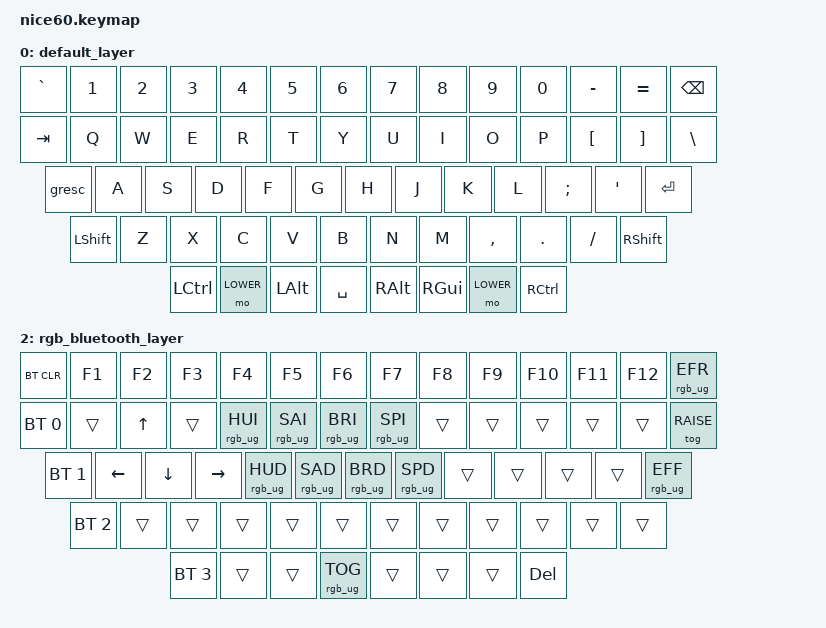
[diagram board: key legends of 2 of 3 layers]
/*
 * Copyright (c) 2021 Nick Winans
 *
 * SPDX-License-Identifier: MIT
 */

#include <behaviors.dtsi>
#include <dt-bindings/zmk/keys.h>
#include <dt-bindings/zmk/rgb.h>
#include <dt-bindings/zmk/bt.h>
#include <dt-bindings/zmk/outputs.h>
#include <dt-bindings/zmk/reset.h>
#include <dt-bindings/zmk/ext_power.h>

#define DEFAULT 0
#define LOWER   1
#define RAISE   2
/ {

behaviors {
        hm: homerow_mods {
            compatible = "zmk,behavior-hold-tap";
            label = "SPACE_FN_MODS";
            #binding-cells = <2>;
            tapping-term-ms = <400>;
            quick_tap_ms = <0>;
            flavor = "tap-preferred";
            bindings = <&mo>, <&kp>;
        };
    };
   
	keymap {
		compatible = "zmk,keymap";
		
		default_layer {
// ------------------------------------------------------------------------------------------
// | ` |  1  |  2  |  3  |  4  |  5  |  6  |  7  |  8  |  9  |  0  |  -  |  =  |   BKSP   |
// | TAB  |  Q  |  W  |  E  |  R  |  T  |  Y  |  U  |  I  |  O  |  P  |  [  |  ]  |   \     |
// | ESC  |  A  |  S  |  D  |  F  |  G  |  H  |  J  |  K  |  L  |  ;  |  '  |     ENTER    |
// |  SHIFT  |  Z  |  X  |  C  |  V  |  B  |  N  |  M  |  ,  |  .  |  /  |      SHIFT       |
// |  CTL  |  LOWER  |  ALT  |            SPACE              |  ALT  |  LOWER  |  WIN |  CTL  |
// ------------------------------------------------------------------------------------------
			bindings = <
	&kp GRAVE &kp N1 &kp N2 &kp N3 &kp N4 &kp N5 &kp N6 &kp N7 &kp N8 &kp N9 &kp N0 &kp MINUS &kp EQUAL  &kp BSPC
	&kp TAB  &kp Q  &kp W  &kp E  &kp R  &kp T  &kp Y  &kp U  &kp I  &kp O  &kp P  &kp LBKT  &kp RBKT  &kp BSLH
	&gresc  &kp A  &kp S  &kp D  &kp F  &kp G  &kp H  &kp J  &kp K  &kp L  &kp SEMI &kp SQT           &kp RET
	&kp LSHFT   &kp Z  &kp X  &kp C  &kp V  &kp B  &kp N  &kp M  &kp COMMA &kp DOT &kp FSLH           &kp RSHFT
	&kp LCTRL &mo LOWER &kp LALT             &kp SPACE                    &kp RALT &kp RGUI  &mo LOWER   &kp RCTRL
			>;
		};
		
		function_media_layer {
// --------------------------------------------------------------------------------------------------
// |       |  F1  |  F2  |  F3  |  F4  |  F5  |  F6  |  F7  |  F8  |  F9  |  F10      |  F11     |  F12     | BKSP |
// |       | BRIDN|BRIUP |      |      |      |      |      |      |      |   PAUSE   |  VOL UP  |  VOL DN  | RAISE |
// |       |      |      |      |      |      |  LT  | DOWN |  UP  |  RT  |           |          |                 |
// |       |      |      |      |      |      |      |      |      |      |           |          |                 |
// |       |      |      |                  SLEEP                         |           |          |          |      |
// --------------------------------------------------------------------------------------------------
			bindings = <
	&trans    &kp F1   &kp F2    &kp F3   &kp F4    &kp F5     &kp F6  &kp F7   &kp F8   &kp F9     &kp F10   &kp F11       &kp F12        &kp BSPC
	&trans    &kp C_BRI_DN   &kp C_BRI_UP    &trans   &trans    &trans     &trans  &trans   &trans   &trans     &kp C_PP  &kp C_VOL_DN  &kp C_VOL_UP   &tog RAISE 
	&trans  &trans  &trans  &trans  &trans  &trans  &kp LEFT  &kp DOWN  &kp UP  &kp RIGHT  &trans &trans           &trans                     
	&trans &trans   &trans    &trans   &trans    &trans  &trans &trans  &trans   &trans  &trans       &trans                     &trans
	&trans    &trans   &trans                            &kp C_SLEEP                                     &trans    &trans        &trans         &trans
			>;
		};

		rgb_bluetooth_layer {
// ------------------------------------------------------------------------------------------------
// | BT CLR | F1  | F2  | F3  | F4  | F5  | F6  | F7  | F8  | F9  | F10  | F11 | F12 | EFFECT REV |
// |  BT 1   |   |  UP |   | HUEUP | SATUP | BRIUP | SPDUP |   |     |    |     |     |  RAISE    |
// |   BT 2   | LT |  DN  | RT | HUEDN | SATDN | BRIDN | SPDDN |   |     |   |     |  EFFECT FORW |
// |    BT 3     |     |      |      |     |     |     |     |     |     |     |                  |
// |   BT 4  |      |      |             TOG RGB                |     |       |       |  DEL  |
// ------------------------------------------------------------------------------------------------
			bindings = <
	&bt BT_CLR   &kp F1    &kp F2    &kp F3  &kp F4           &kp F5          &kp F6          &kp F7          &kp F8   &kp F9   &kp F10  &kp F11 &kp F12  &rgb_ug RGB_EFR
	&bt BT_SEL 0  &trans    &kp UP    &trans  &rgb_ug RGB_HUI  &rgb_ug RGB_SAI &rgb_ug RGB_BRI &rgb_ug RGB_SPI  &trans   &trans   &trans   &trans  &trans    &tog RAISE 
	&bt BT_SEL 1   &kp LEFT  &kp DOWN  &kp RIGHT &rgb_ug RGB_HUD &rgb_ug RGB_SAD &rgb_ug RGB_BRD &rgb_ug RGB_SPD &trans   &trans   &trans   &trans        &rgb_ug RGB_EFF
	&bt BT_SEL 2    &trans    &trans    &trans   &trans          &trans          &trans          &trans          &trans   &trans   &trans                          &trans
	&bt BT_SEL 3  &trans   &trans                            &rgb_ug RGB_TOG                                      &trans      &trans      &trans               &kp DEL
			>;
		};
	};
};
